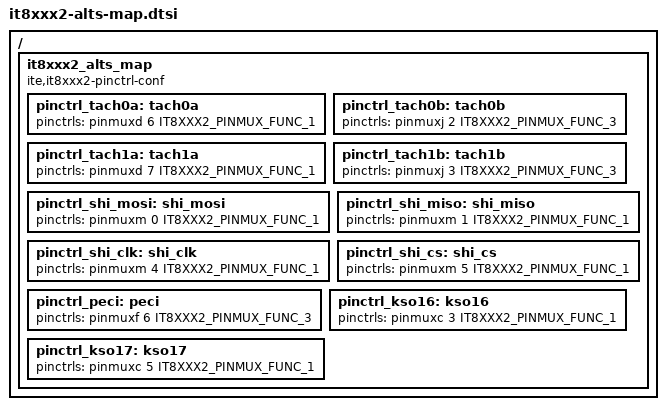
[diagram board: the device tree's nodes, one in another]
/*
 * Copyright (c) 2021 ITE Corporation. All Rights Reserved.
 *
 * SPDX-License-Identifier: Apache-2.0
 */

#include <dt-bindings/pinctrl/it8xxx2-pinctrl.h>

/ {
	it8xxx2_alts_map {
		compatible = "ite,it8xxx2-pinctrl-conf";

		/* Tachometer alternate function */
		pinctrl_tach0a: tach0a {
			pinctrls = <&pinmuxd 6 IT8XXX2_PINMUX_FUNC_1>;
		};
		pinctrl_tach0b: tach0b {
			pinctrls = <&pinmuxj 2 IT8XXX2_PINMUX_FUNC_3>;
		};
		pinctrl_tach1a: tach1a {
			pinctrls = <&pinmuxd 7 IT8XXX2_PINMUX_FUNC_1>;
		};
		pinctrl_tach1b: tach1b {
			pinctrls = <&pinmuxj 3 IT8XXX2_PINMUX_FUNC_3>;
		};

		/* SHI alternate function */
		pinctrl_shi_mosi: shi_mosi {
			pinctrls = <&pinmuxm 0 IT8XXX2_PINMUX_FUNC_1>;
		};
		pinctrl_shi_miso: shi_miso {
			pinctrls = <&pinmuxm 1 IT8XXX2_PINMUX_FUNC_1>;
		};
		pinctrl_shi_clk: shi_clk {
			pinctrls = <&pinmuxm 4 IT8XXX2_PINMUX_FUNC_1>;
		};
		pinctrl_shi_cs: shi_cs {
			pinctrls = <&pinmuxm 5 IT8XXX2_PINMUX_FUNC_1>;
		};

		/* PECI alternate function */
		pinctrl_peci: peci {
			pinctrls = <&pinmuxf 6 IT8XXX2_PINMUX_FUNC_3>;
		};

		/* Keyboard alternate function */
		pinctrl_kso16: kso16 {
			pinctrls = <&pinmuxc 3 IT8XXX2_PINMUX_FUNC_1>;
		};
		pinctrl_kso17: kso17 {
			pinctrls = <&pinmuxc 5 IT8XXX2_PINMUX_FUNC_1>;
		};
	};
};
